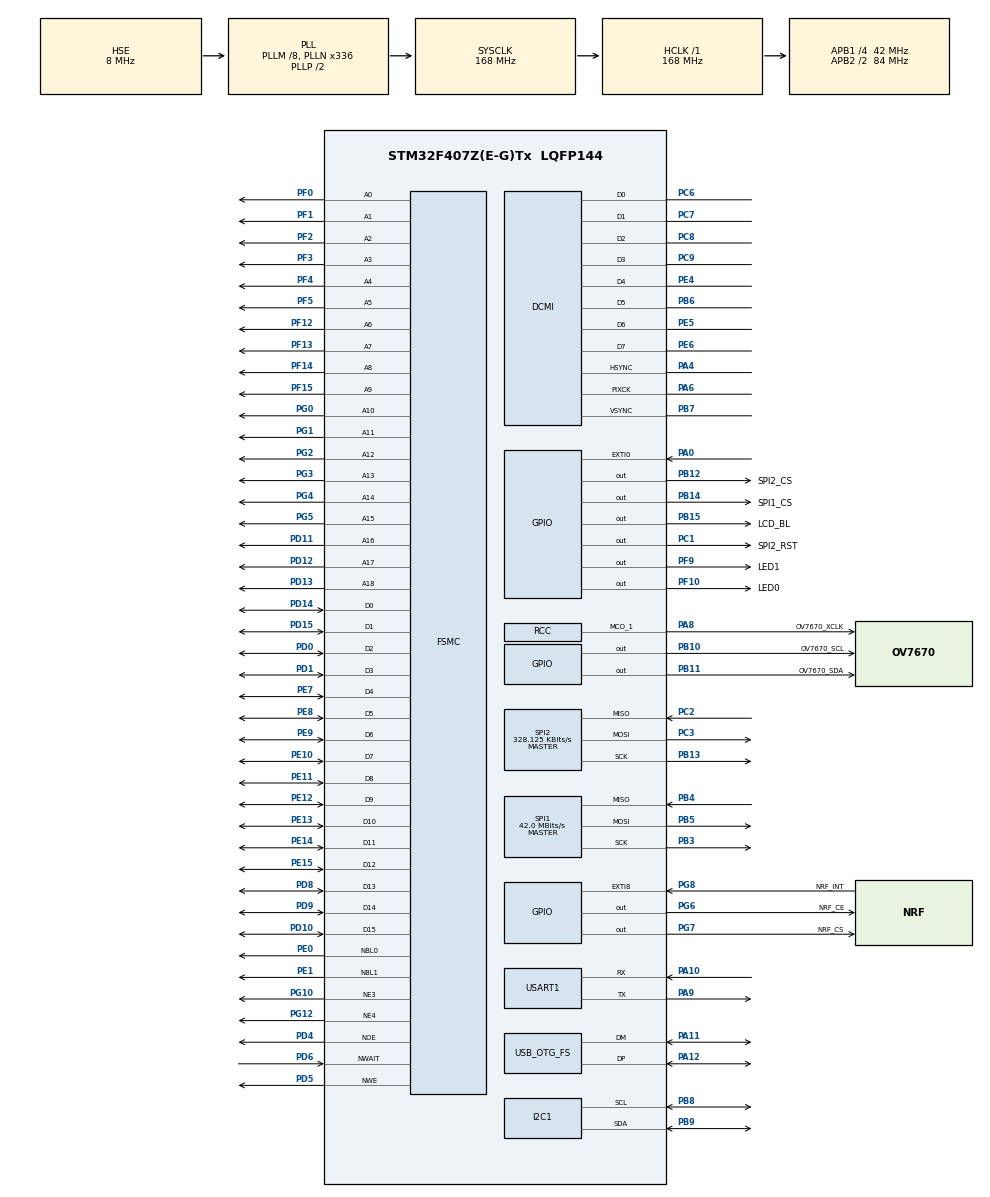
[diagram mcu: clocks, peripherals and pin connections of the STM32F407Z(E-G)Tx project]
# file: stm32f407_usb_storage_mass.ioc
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DCMI.HSPolarity=DCMI_HSPOLARITY_HIGH
DCMI.JPEGMode=DCMI_JPEG_DISABLE
DCMI.PCKPolarity=DCMI_PCKPOLARITY_FALLING
DCMI.VSPolarity=DCMI_VSPOLARITY_HIGH
Dma.DCMI.0.Direction=DMA_PERIPH_TO_MEMORY
Dma.DCMI.0.FIFOMode=DMA_FIFOMODE_DISABLE
Dma.DCMI.0.Instance=DMA2_Stream1
Dma.DCMI.0.MemDataAlignment=DMA_MDATAALIGN_WORD
Dma.DCMI.0.MemInc=DMA_MINC_ENABLE
Dma.DCMI.0.Mode=DMA_CIRCULAR
Dma.DCMI.0.PeriphDataAlignment=DMA_PDATAALIGN_WORD
Dma.DCMI.0.PeriphInc=DMA_PINC_DISABLE
Dma.DCMI.0.Priority=DMA_PRIORITY_HIGH
Dma.Request0=DCMI
FATFS._CODE_PAGE=850
FATFS._FS_NORTC=0
FATFS._FS_TINY=0
FATFS._MAX_SS=4096
FATFS._MIN_SS=4096
FSMC.AddressSetupTime1=0
FSMC.BusTurnAroundDuration1=0
FSMC.BusTurnAroundDuration2=0
FSMC.DataSetupTime1=8
FSMC.DataSetupTime2=60
FSMC.ExtendedAddressSetupTime1=0
FSMC.ExtendedAddressSetupTime2=9
FSMC.ExtendedBusTurnAroundDuration1=0
FSMC.ExtendedBusTurnAroundDuration2=0
FSMC.ExtendedDataSetupTime1=8
FSMC.ExtendedDataSetupTime2=8
FSMC.ExtendedMode1=FSMC_EXTENDED_MODE_ENABLE
FSMC.ExtendedMode2=FSMC_EXTENDED_MODE_ENABLE
FSMC.WaitSignalPolarity1=FSMC_WAIT_SIGNAL_POLARITY_LOW
FSMC.WriteOperation1=FSMC_WRITE_OPERATION_ENABLE
Mcu.Family=STM32F4
Mcu.Name=STM32F407Z(E-G)Tx
Mcu.Package=LQFP144
NVIC.DCMI_IRQn=true\:1\:0\:true\:false\:true\:true\:true
NVIC.DMA2_Stream1_IRQn=true\:1\:0\:true\:false\:true\:false\:true
NVIC.EXTI0_IRQn=true\:2\:0\:true\:false\:true\:true\:true
NVIC.EXTI9_5_IRQn=true\:0\:0\:false\:false\:true\:true\:true
NVIC.OTG_FS_IRQn=true\:0\:0\:false\:false\:true\:false\:true
NVIC.PriorityGroup=NVIC_PRIORITYGROUP_2
NVIC.USART1_IRQn=true\:3\:3\:true\:false\:true\:true\:true
PA0-WKUP.GPIO_ModeDefaultEXTI=GPIO_MODE_IT_RISING
PA0-WKUP.GPIO_PuPd=GPIO_PULLDOWN
PA0-WKUP.Signal=GPXTI0
PA10.Mode=Asynchronous
PA10.Signal=USART1_RX
PA11.GPIO_PuPd=GPIO_NOPULL
PA11.Mode=Device_Only
PA11.Signal=USB_OTG_FS_DM
PA12.GPIO_PuPd=GPIO_NOPULL
PA12.Mode=Device_Only
PA12.Signal=USB_OTG_FS_DP
PA13.Mode=Serial_Wire
PA13.Signal=SYS_JTMS-SWDIO
PA14.Mode=Serial_Wire
PA14.Signal=SYS_JTCK-SWCLK
PA4.Mode=Slave_8_bits_External_Synchro
PA4.Signal=DCMI_HSYNC
PA6.Mode=Slave_8_bits_External_Synchro
PA6.Signal=DCMI_PIXCK
PA8.GPIO_Label=OV7670_XCLK
PA8.Mode=Clock-out-1
PA8.Signal=RCC_MCO_1
PA9.Mode=Asynchronous
PA9.Signal=USART1_TX
PB10.GPIO_Label=OV7670_SCL
PB10.GPIO_PuPd=GPIO_PULLUP
PB10.GPIO_Speed=GPIO_SPEED_FREQ_VERY_HIGH
PB10.PinState=GPIO_PIN_SET
PB10.Signal=GPIO_Output
PB11.GPIO_Label=OV7670_SDA
PB11.GPIO_ModeDefaultOutputPP=GPIO_MODE_OUTPUT_PP
PB11.GPIO_PuPd=GPIO_PULLUP
PB11.GPIO_Speed=GPIO_SPEED_FREQ_VERY_HIGH
PB11.PinState=GPIO_PIN_SET
PB11.Signal=GPIO_Output
PB12.GPIO_Label=SPI2_CS
PB12.GPIO_Speed=GPIO_SPEED_FREQ_VERY_HIGH
PB12.PinState=GPIO_PIN_RESET
PB12.Signal=GPIO_Output
PB13.Mode=Full_Duplex_Master
PB13.Signal=SPI2_SCK
PB14.GPIO_Label=SPI1_CS
PB14.GPIO_ModeDefaultOutputPP=GPIO_MODE_OUTPUT_PP
PB14.GPIO_PuPd=GPIO_NOPULL
PB14.GPIO_Speed=GPIO_SPEED_FREQ_VERY_HIGH
PB14.PinState=GPIO_PIN_SET
PB14.Signal=GPIO_Output
PB15.GPIO_Label=LCD_BL
PB15.GPIO_PuPd=GPIO_PULLUP
PB15.GPIO_Speed=GPIO_SPEED_FREQ_VERY_HIGH
PB15.Signal=GPIO_Output
PB3.Mode=Full_Duplex_Master
PB3.Signal=SPI1_SCK
PB4.Mode=Full_Duplex_Master
PB4.Signal=SPI1_MISO
PB5.Mode=Full_Duplex_Master
PB5.Signal=SPI1_MOSI
PB6.Mode=Slave_8_bits_External_Synchro
PB6.Signal=DCMI_D5
PB7.Mode=Slave_8_bits_External_Synchro
PB7.Signal=DCMI_VSYNC
PB8.Mode=I2C
PB8.Signal=I2C1_SCL
PB9.Mode=I2C
PB9.Signal=I2C1_SDA
PC1.GPIO_Label=SPI2_RST
PC1.GPIO_ModeDefaultOutputPP=GPIO_MODE_OUTPUT_PP
PC1.GPIO_PuPd=GPIO_NOPULL
PC1.GPIO_Speed=GPIO_SPEED_FREQ_VERY_HIGH
PC1.PinState=GPIO_PIN_RESET
PC1.Signal=GPIO_Output
PC2.Mode=Full_Duplex_Master
PC2.Signal=SPI2_MISO
PC3.Mode=Full_Duplex_Master
PC3.Signal=SPI2_MOSI
PC6.Mode=Slave_8_bits_External_Synchro
PC6.Signal=DCMI_D0
PC7.Mode=Slave_8_bits_External_Synchro
PC7.Signal=DCMI_D1
PC8.Mode=Slave_8_bits_External_Synchro
PC8.Signal=DCMI_D2
PC9.Mode=Slave_8_bits_External_Synchro
PC9.Signal=DCMI_D3
PD0.Signal=FSMC_D2_DA2
PD1.Signal=FSMC_D3_DA3
PD10.Signal=FSMC_D15_DA15
PD11.Signal=FSMC_A16_CLE
PD12.Signal=FSMC_A17_ALE
PD13.Signal=FSMC_A18
PD14.Signal=FSMC_D0_DA0
PD15.Signal=FSMC_D1_DA1
PD4.Signal=FSMC_NOE
PD5.Signal=FSMC_NWE
PD6.Signal=FSMC_NWAIT
PD8.Signal=FSMC_D13_DA13
PD9.Signal=FSMC_D14_DA14
PE0.Signal=FSMC_NBL0
PE1.Signal=FSMC_NBL1
PE10.Signal=FSMC_D7_DA7
PE11.Signal=FSMC_D8_DA8
PE12.Signal=FSMC_D9_DA9
PE13.Signal=FSMC_D10_DA10
PE14.Signal=FSMC_D11_DA11
PE15.Signal=FSMC_D12_DA12
PE4.Mode=Slave_8_bits_External_Synchro
PE4.Signal=DCMI_D4
PE5.Mode=Slave_8_bits_External_Synchro
PE5.Signal=DCMI_D6
PE6.Mode=Slave_8_bits_External_Synchro
PE6.Signal=DCMI_D7
PE7.Signal=FSMC_D4_DA4
PE8.Signal=FSMC_D5_DA5
PE9.Signal=FSMC_D6_DA6
PF0.Signal=FSMC_A0
PF1.Signal=FSMC_A1
PF10.GPIO_Label=LED0
PF10.GPIO_ModeDefaultOutputPP=GPIO_MODE_OUTPUT_OD
PF10.GPIO_PuPd=GPIO_PULLUP
PF10.GPIO_Speed=GPIO_SPEED_FREQ_VERY_HIGH
PF10.PinState=GPIO_PIN_SET
PF10.Signal=GPIO_Output
PF12.Signal=FSMC_A6
PF13.Signal=FSMC_A7
PF14.Signal=FSMC_A8
PF15.Signal=FSMC_A9
PF2.Signal=FSMC_A2
PF3.Signal=FSMC_A3
PF4.Signal=FSMC_A4
PF5.Signal=FSMC_A5
PF9.GPIO_Label=LED1
PF9.GPIO_ModeDefaultOutputPP=GPIO_MODE_OUTPUT_OD
PF9.GPIO_PuPd=GPIO_PULLUP
PF9.GPIO_Speed=GPIO_SPEED_FREQ_VERY_HIGH
PF9.PinState=GPIO_PIN_SET
PF9.Signal=GPIO_Output
PG0.Signal=FSMC_A10
PG1.Signal=FSMC_A11
PG10.Mode=NorPsramChipSelect3_1
PG10.Signal=FSMC_NE3
PG12.Mode=NorPsramChipSelect4_2
PG12.Signal=FSMC_NE4
PG2.Signal=FSMC_A12
PG3.Signal=FSMC_A13
PG4.Signal=FSMC_A14
PG5.Signal=FSMC_A15
PG6.GPIO_Label=NRF_CE
PG6.GPIO_Speed=GPIO_SPEED_FREQ_VERY_HIGH
PG6.Signal=GPIO_Output
PG7.GPIO_Label=NRF_CS
PG7.GPIO_Speed=GPIO_SPEED_FREQ_VERY_HIGH
PG7.Signal=GPIO_Output
PG8.GPIO_Label=NRF_INT
PG8.GPIO_ModeDefaultEXTI=GPIO_MODE_IT_FALLING
PG8.GPIO_PuPd=GPIO_PULLUP
PG8.Signal=GPXTI8
PH0-OSC_IN.Mode=HSE-External-Oscillator
PH0-OSC_IN.Signal=RCC_OSC_IN
PH1-OSC_OUT.Mode=HSE-External-Oscillator
PH1-OSC_OUT.Signal=RCC_OSC_OUT
ProjectManager.HeapSize=0x2000
ProjectManager.StackSize=0x2000
ProjectManager.TargetToolchain=MDK-ARM V5
RCC.48MHZClocksFreq_Value=48000000
RCC.AHBFreq_Value=168000000
RCC.APB1CLKDivider=RCC_HCLK_DIV4
RCC.APB1Freq_Value=42000000
RCC.APB1TimFreq_Value=84000000
RCC.APB2CLKDivider=RCC_HCLK_DIV2
RCC.APB2Freq_Value=84000000
RCC.APB2TimFreq_Value=168000000
RCC.CortexFreq_Value=168000000
RCC.HCLKFreq_Value=168000000
RCC.HSE_VALUE=8000000
RCC.HSI_VALUE=16000000
RCC.LSE_VALUE=32768
RCC.PLLM=8
RCC.PLLN=336
RCC.PLLQ=7
RCC.RCC_MCO1Source=RCC_MCO1SOURCE_PLLCLK
RCC.RCC_MCODiv1=RCC_MCODIV_4
RCC.SYSCLKFreq_VALUE=168000000
RCC.SYSCLKSource=RCC_SYSCLKSOURCE_PLLCLK
RCC.VCOOutputFreq_Value=336000000
SH.FSMC_A0.0=FSMC_A0,19b-a1
SH.FSMC_A1.0=FSMC_A1,19b-a1
SH.FSMC_A10.0=FSMC_A10,19b-a1
SH.FSMC_A11.0=FSMC_A11,19b-a1
SH.FSMC_A12.0=FSMC_A12,19b-a1
SH.FSMC_A13.0=FSMC_A13,19b-a1
SH.FSMC_A14.0=FSMC_A14,19b-a1
SH.FSMC_A15.0=FSMC_A15,19b-a1
SH.FSMC_A16_CLE.0=FSMC_A16,19b-a1
SH.FSMC_A17_ALE.0=FSMC_A17,19b-a1
SH.FSMC_A18.0=FSMC_A18,19b-a1
SH.FSMC_A2.0=FSMC_A2,19b-a1
SH.FSMC_A3.0=FSMC_A3,19b-a1
SH.FSMC_A4.0=FSMC_A4,19b-a1
SH.FSMC_A5.0=FSMC_A5,19b-a1
SH.FSMC_A6.0=FSMC_A6,19b-a1
SH.FSMC_A6.1=FSMC_A6,A6_2
SH.FSMC_A7.0=FSMC_A7,19b-a1
SH.FSMC_A8.0=FSMC_A8,19b-a1
SH.FSMC_A9.0=FSMC_A9,19b-a1
SH.FSMC_D0_DA0.0=FSMC_D0,16b-d1
SH.FSMC_D0_DA0.1=FSMC_D0,16b-d2
SH.FSMC_D10_DA10.0=FSMC_D10,16b-d1
SH.FSMC_D10_DA10.1=FSMC_D10,16b-d2
SH.FSMC_D11_DA11.0=FSMC_D11,16b-d1
SH.FSMC_D11_DA11.1=FSMC_D11,16b-d2
SH.FSMC_D12_DA12.0=FSMC_D12,16b-d1
SH.FSMC_D12_DA12.1=FSMC_D12,16b-d2
SH.FSMC_D13_DA13.0=FSMC_D13,16b-d1
SH.FSMC_D13_DA13.1=FSMC_D13,16b-d2
SH.FSMC_D14_DA14.0=FSMC_D14,16b-d1
SH.FSMC_D14_DA14.1=FSMC_D14,16b-d2
SH.FSMC_D15_DA15.0=FSMC_D15,16b-d1
SH.FSMC_D15_DA15.1=FSMC_D15,16b-d2
SH.FSMC_D1_DA1.0=FSMC_D1,16b-d1
SH.FSMC_D1_DA1.1=FSMC_D1,16b-d2
SH.FSMC_D2_DA2.0=FSMC_D2,16b-d1
SH.FSMC_D2_DA2.1=FSMC_D2,16b-d2
SH.FSMC_D3_DA3.0=FSMC_D3,16b-d1
SH.FSMC_D3_DA3.1=FSMC_D3,16b-d2
SH.FSMC_D4_DA4.0=FSMC_D4,16b-d1
SH.FSMC_D4_DA4.1=FSMC_D4,16b-d2
SH.FSMC_D5_DA5.0=FSMC_D5,16b-d1
SH.FSMC_D5_DA5.1=FSMC_D5,16b-d2
SH.FSMC_D6_DA6.0=FSMC_D6,16b-d1
SH.FSMC_D6_DA6.1=FSMC_D6,16b-d2
SH.FSMC_D7_DA7.0=FSMC_D7,16b-d1
SH.FSMC_D7_DA7.1=FSMC_D7,16b-d2
SH.FSMC_D8_DA8.0=FSMC_D8,16b-d1
SH.FSMC_D8_DA8.1=FSMC_D8,16b-d2
SH.FSMC_D9_DA9.0=FSMC_D9,16b-d1
SH.FSMC_D9_DA9.1=FSMC_D9,16b-d2
SH.FSMC_NBL0.0=FSMC_NBL0,2ByteEnable1
SH.FSMC_NBL1.0=FSMC_NBL1,2ByteEnable1
SH.FSMC_NOE.0=FSMC_NOE,Sram1
SH.FSMC_NOE.1=FSMC_NOE,Lcd2
SH.FSMC_NWAIT.0=FSMC_NWAIT,AsynchronousWait1
SH.FSMC_NWE.0=FSMC_NWE,Sram1
SH.FSMC_NWE.1=FSMC_NWE,Lcd2
SPI1.BaudRatePrescaler=SPI_BAUDRATEPRESCALER_2
SPI1.CLKPhase=SPI_PHASE_1EDGE
SPI1.CLKPolarity=SPI_POLARITY_LOW
SPI1.CalculateBaudRate=42.0 MBits/s
SPI1.Direction=SPI_DIRECTION_2LINES
SPI1.Mode=SPI_MODE_MASTER
SPI1.VirtualType=VM_MASTER
SPI2.BaudRatePrescaler=SPI_BAUDRATEPRESCALER_128
SPI2.CLKPhase=SPI_PHASE_1EDGE
SPI2.CLKPolarity=SPI_POLARITY_LOW
SPI2.CalculateBaudRate=328.125 KBits/s
SPI2.DataSize=SPI_DATASIZE_8BIT
SPI2.Direction=SPI_DIRECTION_2LINES
SPI2.Mode=SPI_MODE_MASTER
SPI2.VirtualType=VM_MASTER
TIM14.AutoReloadPreload=TIM_AUTORELOAD_PRELOAD_DISABLE
TIM14.ClockDivision=TIM_CLOCKDIVISION_DIV1
TIM14.Period=1000
TIM14.Prescaler=83
USART1.VirtualMode=VM_ASYNC
USB_DEVICE.CLASS_NAME_FS=MSC
USB_DEVICE.MSC_MEDIA_PACKET-MSC_FS=4096
USB_DEVICE.USBD_SELF_POWERED-MSC_FS=1
USB_DEVICE.VirtualMode-MSC_FS=Msc
USB_DEVICE.VirtualModeFS=Msc_FS
USB_OTG_FS.VirtualMode=Device_Only
VP_CRC_VS_CRC.Mode=CRC_Activate
VP_FATFS_VS_Generic.Mode=User_defined
VP_TIM14_VS_ClockSourceINT.Mode=Enable_Timer
VP_USB_DEVICE_VS_USB_DEVICE_MSC_FS.Mode=MSC_FS
board=custom

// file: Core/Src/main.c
/* USER CODE BEGIN Header */
/**
  ******************************************************************************
  * @file           : main.c
  * @brief          : Main program body
  ******************************************************************************
  * @attention
  *
  * <h2><center>&copy; Copyright (c) 2019 STMicroelectronics.
  * All rights reserved.</center></h2>
  *
  * This software component is licensed by ST under Ultimate Liberty license
  * SLA0044, the "License"; You may not use this file except in compliance with
  * the License. You may obtain a copy of the License at:
  *                             www.st.com/SLA0044
  *
  ******************************************************************************
  */
/* USER CODE END Header */

#include "main.h"
#include "crc.h"
#include "dcmi.h"
#include "dma.h"
#include "fatfs.h"
#include "i2c.h"
#include "spi.h"
#include "tim.h"
#include "usart.h"
#include "usb_device.h"
#include "gpio.h"
#include "fsmc.h"

/* USER CODE BEGIN Includes */
#include "bsp_w25qxx.h"
#include "bsp_sram.h"
#include "bsp_led.h"
#include "bsp_lcd.h"
#include "bsp_ov7670.h"
#include "bsp_at24cxx.h"
#include "bsp_delay.h"
#include "bsp_button.h"
#include "bsp_enc28j60.h"
#include "bsp_comm.h"
#include "bsp_nrf24lxx.h"
/* USER CODE END Includes */

/* USER CODE BEGIN PV */
//uint8_t CAMERA_BUF[1024*1024] __attribute__(( section(".ARM.__at_0x68000000") )) ={0};
#define CAMERA_BUF 0x68000000
/* USER CODE END PV */

void SystemClock_Config(void);

/* USER CODE BEGIN 0 */
	typedef struct {
		//head
		uint8_t 	bfType[2];	// = {'B','M'};	//windows
		uint32_t 	bfSize;			//byte
		uint16_t	bfReserved1,bfReserved2;
		uint32_t 	bfOffBits;	//offset of image data
		//information
		uint32_t	biSize;			//size of information	/	byte
		uint32_t	biWidth,biHeight;	//pixel
		uint16_t	biPlanes;		//always 1
		uint16_t	biBitCount;	//4,8,16,24,32	color bit
		uint32_t	biCompression;	//0	no
		uint32_t	biSizeImage;		//size of image	/ byte
		int32_t		biXPelsPerMeter,biYPelsPerMeter;
		uint32_t	biClrUsed;
		uint32_t	biClrImportant;
		uint8_t 	Plate[64];
	}	BMP_HEAD;			//54BYTE
uint8_t plate[64] = {	0x00,0x00,0x00,0x00,0x00,0x00,0x80,0x00,
											0x00,0x80,0x00,0x00,0x00,0x80,0x80,0x00,
											0x80,0x00,0x00,0x00,0x80,0x00,0x80,0x00,
											0x80,0x80,0x00,0x00,0x80,0x80,0x80,0x00,
											0xc0,0xc0,0xc0,0x00,0x00,0x00,0xff,0x00,
											0x00,0xff,0x00,0x00,0x00,0xff,0xff,0x00,
											0xff,0x00,0x00,0x00,0xff,0x00,0xff,0x00,
											0xff,0xff,0x00,0x00,0xff,0xff,0xff,0x00	};

void InitBmp(uint32_t addr)
{
	BMP_HEAD *bmp = (BMP_HEAD *)addr;
	bmp->bfType[0] = 'B';
	bmp->bfType[1] = 'M';
	bmp->bfSize = sizeof(BMP_HEAD) + 240*320/2;	//sizeof(BMP_HEAD) + 240*320*(24/8);	//0x76960000
	bmp->bfOffBits = (uint32_t)bmp->Plate-addr;	//sizeof(BMP_HEAD);								//0x76000000
	bmp->bfReserved1 = 0;
	bmp->bfReserved2 = 0;

	bmp->biSize = 40;										//0x28000000
	bmp->biWidth = 240;									//0xf0000000
	bmp->biHeight = 320;								//0x40010000
	bmp->biPlanes = 1;									//0x0100
	bmp->biBitCount = 4;								//0x0400
	bmp->biCompression = 0;							//0x00000000
	bmp->biSizeImage = 0;								//0x00960000
	bmp->biXPelsPerMeter = 0;						//0x00000000
	bmp->biYPelsPerMeter = 0;						//0x00000000
	bmp->biClrUsed = 0;
	bmp->biClrImportant = 0;
	memcpy(bmp->Plate,plate,64);
}
/* USER CODE END 0 */

int main(void)
{

  /* MCU Configuration--------------------------------------------------------*/

  /* Reset of all peripherals, Initializes the Flash interface and the Systick. */
  HAL_Init();

  /* Configure the system clock */
  SystemClock_Config();

  /* Initialize all configured peripherals */
  MX_GPIO_Init();
  MX_DMA_Init();
  MX_USART1_UART_Init();
  MX_USB_DEVICE_Init();
  MX_SPI1_Init();
  MX_FATFS_Init();
  MX_FSMC_Init();
  MX_DCMI_Init();
  MX_I2C1_Init();
  MX_TIM14_Init();
  MX_CRC_Init();
  MX_SPI2_Init();
  /* USER CODE BEGIN 2 */
	#if 1	//basic informaton
	printf("\r\n*****BASIC INFORMATION*****\r\n");
	printf("Hal Version:%X\r\n", HAL_GetHalVersion());
	printf("HCLK Freq: %.2f MHz\r\n", HAL_RCC_GetHCLKFreq()/1.0/1000/1000);
	printf("PCLK1 Freq: %.2f MHz\r\n", HAL_RCC_GetPCLK1Freq()/1.0/1000/1000);
	printf("PCLK2 Freq: %.2f MHz\r\n", HAL_RCC_GetPCLK2Freq()/1.0/1000/1000);
	printf("SysTick Freq: %d Hz\r\n", 1000/(int)HAL_GetTickFreq());
	printf("Device ID:%X\r\n", HAL_GetDEVID());
	printf("Device Revision ID:%X\r\n", HAL_GetREVID());
	printf("Device UID : %X%X%X\r\n", HAL_GetUIDw0(),HAL_GetUIDw1(),HAL_GetUIDw2());
	#endif
	#if 0 //w25q
	printf("\r\n*****BSP INIT*****\r\n");
	BSP_W25QXX_INIT(0);
	printf("Flash Type:%s \r\n", bsp_w25qxx.name);
	printf("Flash Unique ID:%llX \r\n", bsp_w25qxx.unique_id);
	printf("Flash Capicity:%.2f KB\r\n", bsp_w25qxx.capicity/1024.0);
	#endif
	#if 0	//lcd
	BSP_LCD_INIT();
	printf("LCD Type:%s\r\n", bsp_lcd.name);
	printf("LCD ID:%X\r\n", bsp_lcd.id);
	printf("LCD Resolution: %dX%d\r\n", bsp_lcd.height, bsp_lcd.width);
	#endif
	#if 0 //at24c
	uint8_t str[8] = {0};
//	BSP_AT24CXX_WRITE(0,str,sizeof(str));
//	printf("EEPROM Write: %s\r\n",str);
	BSP_AT24CXX_READ(0,str,7);
	printf("EEPROM Read: %s\r\n",str);
	#endif
	#if 1 //comm
	BSP_COMMUNICATE_INIT();
	#endif
	#if 0 //fatfs
	retUSER = f_mount(&USERFatFS, (const TCHAR*)USERPath, 1) ;
	if(retUSER == FR_OK){
		printf("f_mount() disk 0:/ sucessful!!\r\n");
//		uint8_t mkfsBuffer[8192] = {0};
//		retUSER = f_mkfs(USERPath, FM_FAT, 4096, mkfsBuffer, 8192);
//		if(retUSER == FR_OK){
			retUSER = f_open(&USERFile, "0:/test2.txt", FA_OPEN_EXISTING | FA_READ | FA_WRITE);
			if(retUSER == FR_OK){
				TCHAR context[512] = {0};
				UINT bw = 0;
				printf("f_open() test2.txt sucessful!!\r\n");
				//retUSER = f_write(&USERFile, (const TCHAR*)context, sizeof(context), &bw);
				retUSER = f_read(&USERFile, (TCHAR*)context, sizeof(context), &bw);
				printf("%s\r\n", context);
				retUSER = f_close(&USERFile);
			}else{
				printf("f_open() test.txt faild!!\r\n");
			}
//		}
	}
	#endif
	#if 0 //ov7670
	BSP_OV_INIT();
	printf("Cemera ID:%X\r\n", bsp_ov7670.id);
	printf("Cemera Manufactory ID:%X\r\n", bsp_ov7670.mftr_id);
	BSP_OV_CONTINUOUS_START((uint32_t)CAMERA_BUF);
	#endif
	#if 0
	BSP_NRF24LXX_INIT();
  #endif

	#if 0
//	BSP_ENC28J60_CS_SELECTED(1);
//	printf("ETH CARD:%X\r\n", BSP_ENC28J60_READ((EIE & 0x1f)));
//	printf("ETH CARD:%X\r\n", BSP_ENC28J60_READ(0xFF));	//
//	printf("ETH CARD:%X\r\n", BSP_ENC28J60_READ(0xFF)); //EIE			00
//	printf("ETH CARD:%X\r\n", BSP_ENC28J60_READ(0xFF)); //EIR			00
//	printf("ETH CARD:%X\r\n", BSP_ENC28J60_READ(0xFF)); //ESTAT		01
//	printf("ETH CARD:%X\r\n", BSP_ENC28J60_READ(0xFF)); //ECON2		80
//	printf("ETH CARD:%X\r\n", BSP_ENC28J60_READ(0xFF)); //ECON1		00
//	printf("ETH CARD:%X\r\n", BSP_ENC28J60_READ(0xFF)); //ERDPTL	FA
//	printf("ETH CARD:%X\r\n", BSP_ENC28J60_READ(0xFF)); //ERDPTH	05
//	printf("ETH CARD:%X\r\n", BSP_ENC28J60_READ(0xFF)); //EWRPTL	00
//	BSP_ENC28J60_CS_SELECTED(0);

//	BSP_ENC28J60_CS_SELECTED(1);
//	printf("ETH CARD:%X\r\n", BSP_ENC28J60_READ((EIR & 0x1f)));
//	printf("ETH CARD:%X\r\n", BSP_ENC28J60_READ(0xFF));	//
//	printf("ETH CARD:%X\r\n", BSP_ENC28J60_READ(0xFF)); //EIR			00
//	printf("ETH CARD:%X\r\n", BSP_ENC28J60_READ(0xFF)); //ESTAT		01
//	printf("ETH CARD:%X\r\n", BSP_ENC28J60_READ(0xFF)); //ECON2		80
//	printf("ETH CARD:%X\r\n", BSP_ENC28J60_READ(0xFF)); //ECON1		00
//	printf("ETH CARD:%X\r\n", BSP_ENC28J60_READ(0xFF)); //ERDPTL	FA
//	printf("ETH CARD:%X\r\n", BSP_ENC28J60_READ(0xFF)); //ERDPTH	05
//	printf("ETH CARD:%X\r\n", BSP_ENC28J60_READ(0xFF)); //EWRPTL	00
//	BSP_ENC28J60_CS_SELECTED(0);

//	BSP_ENC28J60_CS_SELECTED(1);
//	printf("ETH CARD:%X\r\n", BSP_ENC28J60_READ((ECON1 & 0x1f)));
//	printf("ETH CARD:%X\r\n", BSP_ENC28J60_READ(0xFF)); //ECON1	00
//	printf("ETH CARD:%X\r\n", BSP_ENC28J60_READ(0xFF)); //ECON1	00
//	BSP_ENC28J60_CS_SELECTED(0);

	uint8_t enc28j60_MAC[6] = {0x01, 0x02, 0x03, 0x04, 0x05, 0x06};
	//BSP_ENC28J60_INIT(enc28j60_MAC);
	printf("BSP_ENC28J60_GET_REV:%X \r\n",BSP_ENC28J60_GET_REV());
//
//	BSP_ENC28J60_CS_SELECTED(1);
//	BSP_ENC28J60_READ(ENC28J_REG(EIE)|WCR);
//	printf("ETH CARD:%X\r\n", BSP_ENC28J60_READ(0x01)); //ECON2		80
//	BSP_ENC28J60_CS_SELECTED(0);
//
//	BSP_ENC28J60_CS_SELECTED(1);
//	BSP_ENC28J60_READ(ENC28J_REG(EIR)|WCR);
//	printf("ETH CARD:%X\r\n", BSP_ENC28J60_READ(0x02)); //ECON2		80
//	BSP_ENC28J60_CS_SELECTED(0);
//
//	BSP_ENC28J60_CS_SELECTED(1);
//	BSP_ENC28J60_READ(ENC28J_REG(ECON1)|WCR);
//	printf("ETH CARD:%X\r\n", BSP_ENC28J60_READ(0x02)); //ECON2		80
//	BSP_ENC28J60_CS_SELECTED(0);
	#endif

#if 0
	BMP_HEAD bmp={0};
	InitBmp((uint32_t)&bmp);
#endif
  /* USER CODE END 2 */

  /* Infinite loop */
  while (1)
  {

    /* USER CODE BEGIN 3 */

//		BSP_LED_TOGGLE(1);
		BSP_DELAY(0, 500, 0);
		if(GET_KEY()!=0)
		{
			UINT bw = 0;
			BSP_DELAY(0,20,0);

			#if 0
			uint8_t dat[32] = "nrf24l01plus test string";
			BSP_NRF24LXX_TRANSMIT(0, dat, 32);
			//BSP_NRF24LXX_TRANSMIT_NACK(0, dat, 32);
			#endif

			#if 0
			FIL mybmp;
			retUSER = f_open(&USERFile, "0:/kkp.txt", FA_OPEN_ALWAYS | FA_READ | FA_WRITE);
			if(retUSER == FR_OK){
				BSP_LED_TOGGLE(1);
				retUSER = f_write(&USERFile, (const TCHAR*)(&bmp), sizeof(BMP_HEAD), &bw);
				retUSER = f_write(&USERFile, (const TCHAR*)(0x68000000), 240*320*2, &bw);
				retUSER = f_close(&USERFile);
				printf("f_open() kkp.bmp sucessful!!\r\nwrite in %d byte\r\n",bw);
			}else{
				printf("f_open() kkp.bmp failed!!\r\n");
			}
			#endif
		}

  }
  /* USER CODE END 3 */
}

void SystemClock_Config(void)
{
  RCC_OscInitTypeDef RCC_OscInitStruct = {0};
  RCC_ClkInitTypeDef RCC_ClkInitStruct = {0};

  /** Configure the main internal regulator output voltage
  */
  __HAL_RCC_PWR_CLK_ENABLE();
  __HAL_PWR_VOLTAGESCALING_CONFIG(PWR_REGULATOR_VOLTAGE_SCALE1);
  /** Initializes the CPU, AHB and APB busses clocks
  */
  RCC_OscInitStruct.OscillatorType = RCC_OSCILLATORTYPE_HSE;
  RCC_OscInitStruct.HSEState = RCC_HSE_ON;
  RCC_OscInitStruct.PLL.PLLState = RCC_PLL_ON;
  RCC_OscInitStruct.PLL.PLLSource = RCC_PLLSOURCE_HSE;
  RCC_OscInitStruct.PLL.PLLM = 8;
  RCC_OscInitStruct.PLL.PLLN = 336;
  RCC_OscInitStruct.PLL.PLLP = RCC_PLLP_DIV2;
  RCC_OscInitStruct.PLL.PLLQ = 7;
  if (HAL_RCC_OscConfig(&RCC_OscInitStruct) != HAL_OK)
  {
    Error_Handler();
  }
  /** Initializes the CPU, AHB and APB busses clocks
  */
  RCC_ClkInitStruct.ClockType = RCC_CLOCKTYPE_HCLK|RCC_CLOCKTYPE_SYSCLK
                              |RCC_CLOCKTYPE_PCLK1|RCC_CLOCKTYPE_PCLK2;
  RCC_ClkInitStruct.SYSCLKSource = RCC_SYSCLKSOURCE_PLLCLK;
  RCC_ClkInitStruct.AHBCLKDivider = RCC_SYSCLK_DIV1;
  RCC_ClkInitStruct.APB1CLKDivider = RCC_HCLK_DIV4;
  RCC_ClkInitStruct.APB2CLKDivider = RCC_HCLK_DIV2;

  if (HAL_RCC_ClockConfig(&RCC_ClkInitStruct, FLASH_LATENCY_5) != HAL_OK)
  {
    Error_Handler();
  }
  HAL_RCC_MCOConfig(RCC_MCO1, RCC_MCO1SOURCE_PLLCLK, RCC_MCODIV_4);
}

void Error_Handler(void)
{
}

/************************ (C) COPYRIGHT STMicroelectronics *****END OF FILE****/
